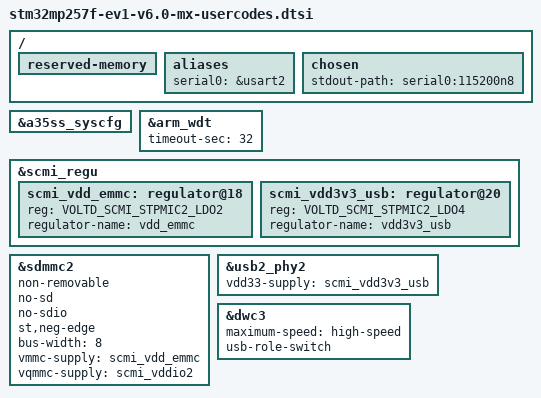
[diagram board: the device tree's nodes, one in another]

#include "../optee/stm32mp257f-ev1-v6.0-mx-resmem.dtsi"
/ {
	reserved-memory{
		/delete-node/ linuxkernel1@84000000 ;
		/delete-node/ linuxkernel2@100000000 ;
	};
};

/{
	aliases {
		serial0 = &usart2;
	};

	chosen {
		stdout-path = "serial0:115200n8";
	};
};

&a35ss_syscfg {
	status = "okay";
};

&arm_wdt {
	timeout-sec = <32>;
	status = "okay";
};

&scmi_regu {
	scmi_vdd_emmc: regulator@18 {
		reg = <VOLTD_SCMI_STPMIC2_LDO2>;
		regulator-name = "vdd_emmc";
	};
	scmi_vdd3v3_usb: regulator@20 {
		reg = <VOLTD_SCMI_STPMIC2_LDO4>;
		regulator-name = "vdd3v3_usb";
	};
};

&sdmmc2 {
	non-removable;
	no-sd;
	no-sdio;
	st,neg-edge;
	bus-width = <8>;
	vmmc-supply = <&scmi_vdd_emmc>;
	vqmmc-supply = <&scmi_vddio2>;
};

&usb2_phy2{
	vdd33-supply = <&scmi_vdd3v3_usb>;
};

&dwc3 {
	maximum-speed = "high-speed";
	usb-role-switch;
};

